# PIC32MZ2048EFM144 register map
Registers are 32-bit, access not given, reset 0x0 unless marked. A register's access mark holds for its fields unless they carry their own. Offsets are from the block's base; [hi:lo] are bit positions; {n}, {i} and the like mark numbered series; 'fields as' and 'values as' point back to an identical list.

## PPS — PPS peripheral
Base 0xBF801404
0x00 INT1R
  [3:0] INT1R
0x04 INT2R
  [3:0] INT2R
0x08 INT3R
  [3:0] INT3R
0x0C INT4R
  [3:0] INT4R
{0xC+4i} T{i}CKR (i=2..9)
  [3:0] T{i}CKR
{0x30+4i} IC{i}R (i=1..9)
  [3:0] IC{i}R
0x5C OCFAR
  [3:0] OCFAR
{0x5C+8i} U{i}RXR (i=1..6)
  [3:0] U{i}RXR
{0x60+8i} U{i}CTSR (i=1..6)
  [3:0] U{i}CTSR
{0x8C+0xC*i} SDI{i}R (i=1..6)
  [3:0] SDI{i}R
{0x90+0xC*i} SS{i}R (i=1..6)
  [3:0] SS{i}R
0xDC C1RXR
  [3:0] C1RXR
0xE0 C2RXR
  [3:0] C2RXR
0xE4 REFCLKI1R
  [3:0] REFCLKI1R
0xEC REFCLKI3R
  [3:0] REFCLKI3R
0xF0 REFCLKI4R
  [3:0] REFCLKI4R
0x134 RPA14R
  [3:0] RPA14R
0x138 RPA15R
  [3:0] RPA15R
{0x13C+4i} RPB{i}R (i=0..3)
  [3:0] RPB{i}R
{0x13C+4i} RPB{i}R (i=5..10)
  [3:0] RPB{i}R
0x174 RPB14R
  [3:0] RPB14R
0x178 RPB15R
  [3:0] RPB15R
{0x17C+4i} RPC{i}R (i=1..4)
  [3:0] RPC{i}R
0x1B0 RPC13R
  [3:0] RPC13R
0x1B4 RPC14R
  [3:0] RPC14R
{0x1BC+4i} RPD{i}R (i=0..7)
  [3:0] RPD{i}R
{0x1BC+4i} RPD{i}R (i=9..12)
  [3:0] RPD{i}R
0x1F4 RPD14R
  [3:0] RPD14R
0x1F8 RPD15R
  [3:0] RPD15R
0x208 RPE3R
  [3:0] RPE3R
0x210 RPE5R
  [3:0] RPE5R
0x21C RPE8R
  [3:0] RPE8R
0x220 RPE9R
  [3:0] RPE9R
{0x23C+4i} RPF{i}R (i=0..5)
  [3:0] RPF{i}R
0x25C RPF8R
  [3:0] RPF8R
0x26C RPF12R
  [3:0] RPF12R
0x270 RPF13R
  [3:0] RPF13R
0x27C RPG0R
  [3:0] RPG0R
0x280 RPG1R
  [3:0] RPG1R
{0x27C+4i} RPG{i}R (i=6..9)
  [3:0] RPG{i}R

## DMAC — DMAC peripheral
Base 0xBF811060
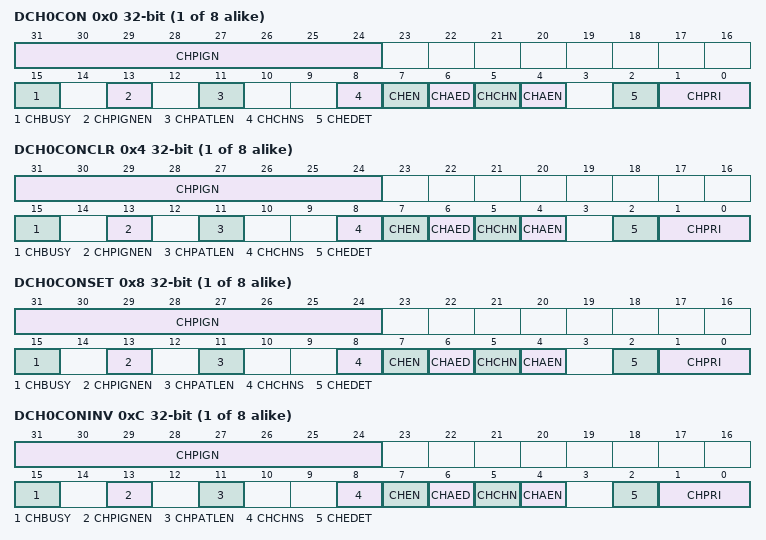
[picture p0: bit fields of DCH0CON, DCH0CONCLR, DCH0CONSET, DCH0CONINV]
{0x0+0xC0*i} DCH{i}CON (i=0..7)
  [31:24] CHPIGN, [15] CHBUSY, [13] CHPIGNEN, [11] CHPATLEN, [8] CHCHNS, [7] CHEN, [6] CHAED, [5] CHCHN, [4] CHAEN, [2] CHEDET, [1:0] CHPRI
{0x4+0xC0*i} DCH{i}CONCLR (i=0..7)
  fields as DCH0CON
{0x8+0xC0*i} DCH{i}CONSET (i=0..7)
  fields as DCH0CON
{0xC+0xC0*i} DCH{i}CONINV (i=0..7)
  fields as DCH0CON
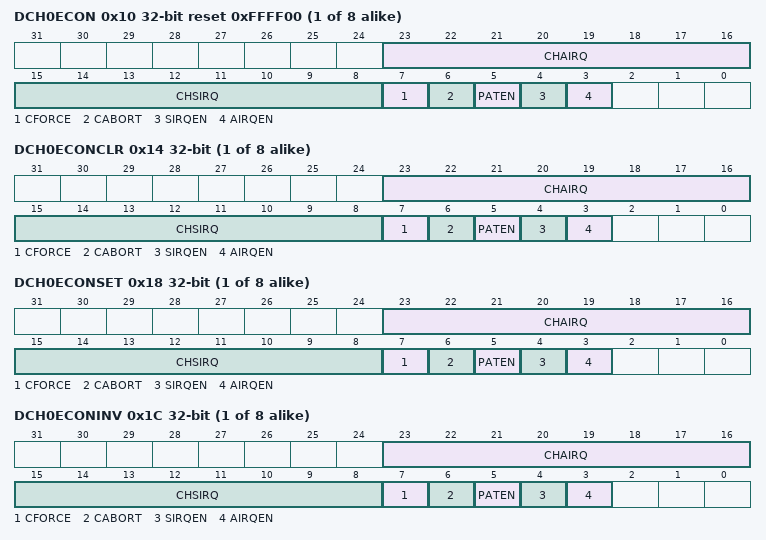
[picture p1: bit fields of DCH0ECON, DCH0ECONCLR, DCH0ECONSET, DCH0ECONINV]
{0x10+0xC0*i} DCH{i}ECON reset 0xFFFF00 (i=0..7)
  [23:16] CHAIRQ, [15:8] CHSIRQ, [7] CFORCE, [6] CABORT, [5] PATEN, [4] SIRQEN, [3] AIRQEN
{0x14+0xC0*i} DCH{i}ECONCLR (i=0..7)
  fields as DCH0ECON
{0x18+0xC0*i} DCH{i}ECONSET (i=0..7)
  fields as DCH0ECON
{0x1C+0xC0*i} DCH{i}ECONINV (i=0..7)
  fields as DCH0ECON
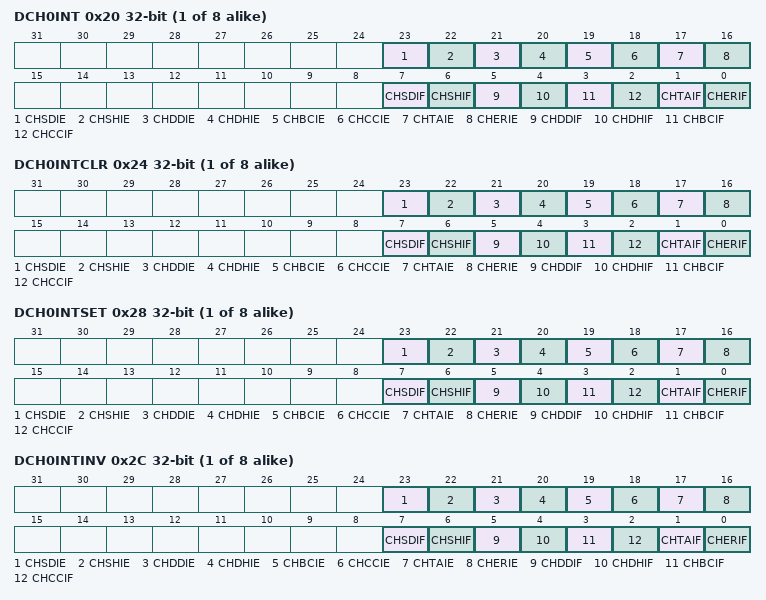
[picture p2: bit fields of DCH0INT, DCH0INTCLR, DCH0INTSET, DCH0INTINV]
{0x20+0xC0*i} DCH{i}INT (i=0..7)
  [23] CHSDIE, [22] CHSHIE, [21] CHDDIE, [20] CHDHIE, [19] CHBCIE, [18] CHCCIE, [17] CHTAIE, [16] CHERIE, [7] CHSDIF, [6] CHSHIF, [5] CHDDIF, [4] CHDHIF, [3] CHBCIF, [2] CHCCIF, [1] CHTAIF, [0] CHERIF
{0x24+0xC0*i} DCH{i}INTCLR (i=0..7)
  fields as DCH0INT
{0x28+0xC0*i} DCH{i}INTSET (i=0..7)
  fields as DCH0INT
{0x2C+0xC0*i} DCH{i}INTINV (i=0..7)
  fields as DCH0INT
{0x30+0xC0*i} DCH{i}SSA (i=0..7)
  [31:0] CHSSA
{0x34+0xC0*i} DCH{i}SSACLR (i=0..7)
  [31:0] CHSSA
{0x38+0xC0*i} DCH{i}SSASET (i=0..7)
  [31:0] CHSSA
{0x3C+0xC0*i} DCH{i}SSAINV (i=0..7)
  [31:0] CHSSA
{0x40+0xC0*i} DCH{i}DSA (i=0..7)
  [31:0] CHDSA
{0x44+0xC0*i} DCH{i}DSACLR (i=0..7)
  [31:0] CHDSA
{0x48+0xC0*i} DCH{i}DSASET (i=0..7)
  [31:0] CHDSA
{0x4C+0xC0*i} DCH{i}DSAINV (i=0..7)
  [31:0] CHDSA
{0x50+0xC0*i} DCH{i}SSIZ (i=0..7)
  [15:0] CHSSIZ
{0x54+0xC0*i} DCH{i}SSIZCLR (i=0..7)
  [15:0] CHSSIZ
{0x58+0xC0*i} DCH{i}SSIZSET (i=0..7)
  [15:0] CHSSIZ
{0x5C+0xC0*i} DCH{i}SSIZINV (i=0..7)
  [15:0] CHSSIZ
{0x60+0xC0*i} DCH{i}DSIZ (i=0..7)
  [15:0] CHDSIZ
{0x64+0xC0*i} DCH{i}DSIZCLR (i=0..7)
  [15:0] CHDSIZ
{0x68+0xC0*i} DCH{i}DSIZSET (i=0..7)
  [15:0] CHDSIZ
{0x6C+0xC0*i} DCH{i}DSIZINV (i=0..7)
  [15:0] CHDSIZ
{0x70+0xC0*i} DCH{i}SPTR (i=0..7)
  [15:0] CHSPTR
{0x74+0xC0*i} DCH{i}SPTRCLR (i=0..7)
  [15:0] CHSPTR
{0x78+0xC0*i} DCH{i}SPTRSET (i=0..7)
  [15:0] CHSPTR
{0x7C+0xC0*i} DCH{i}SPTRINV (i=0..7)
  [15:0] CHSPTR
{0x80+0xC0*i} DCH{i}DPTR (i=0..7)
  [15:0] CHDPTR
{0x84+0xC0*i} DCH{i}DPTRCLR (i=0..7)
  [15:0] CHDPTR
{0x88+0xC0*i} DCH{i}DPTRSET (i=0..7)
  [15:0] CHDPTR
{0x8C+0xC0*i} DCH{i}DPTRINV (i=0..7)
  [15:0] CHDPTR
{0x90+0xC0*i} DCH{i}CSIZ (i=0..7)
  [15:0] CHCSIZ
{0x94+0xC0*i} DCH{i}CSIZCLR (i=0..7)
  [15:0] CHCSIZ
{0x98+0xC0*i} DCH{i}CSIZSET (i=0..7)
  [15:0] CHCSIZ
{0x9C+0xC0*i} DCH{i}CSIZINV (i=0..7)
  [15:0] CHCSIZ
{0xA0+0xC0*i} DCH{i}CPTR (i=0..7)
  [15:0] CHCPTR
{0xA4+0xC0*i} DCH{i}CPTRCLR (i=0..7)
  [15:0] CHCPTR
{0xA8+0xC0*i} DCH{i}CPTRSET (i=0..7)
  [15:0] CHCPTR
{0xAC+0xC0*i} DCH{i}CPTRINV (i=0..7)
  [15:0] CHCPTR
{0xB0+0xC0*i} DCH{i}DAT (i=0..7)
  [15:0] CHPDAT
{0xB4+0xC0*i} DCH{i}DATCLR (i=0..7)
  [15:0] CHPDAT
{0xB8+0xC0*i} DCH{i}DATSET (i=0..7)
  [15:0] CHPDAT
{0xBC+0xC0*i} DCH{i}DATINV (i=0..7)
  [15:0] CHPDAT
